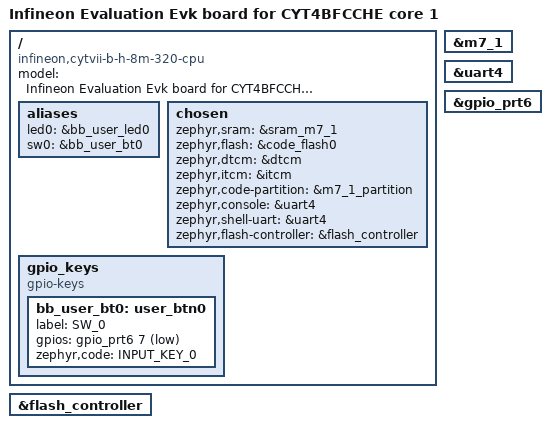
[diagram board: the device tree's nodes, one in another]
/*
 * Copyright (c) 2026 Infineon Technologies AG,
 * or an affiliate of Infineon Technologies AG.
 * Copyright (c) 2026 Linumiz
 *
 * SPDX-License-Identifier: Apache-2.0
 */

/dts-v1/;
#include <arm/infineon/cat1c/traveo/cyt4bf/cyt4bf_m7.dtsi>
#include "cytvii_b_h_8m_320_cpu_common.dtsi"
#include "cytvii_b_h_8m_320_cpu_cyt4bfcche_pinctrl.dtsi"

/ {
	model = "Infineon Evaluation Evk board for CYT4BFCCHE core 1";
	compatible = "infineon,cytvii-b-h-8m-320-cpu", "infineon,cyt4bf";

	aliases {
                led0 = &bb_user_led0;
                sw0 = &bb_user_bt0;
        };

	chosen {
		zephyr,sram = &sram_m7_1;
		zephyr,flash = &code_flash0;
		zephyr,dtcm = &dtcm;
		zephyr,itcm = &itcm;
		zephyr,code-partition = &m7_1_partition;
		zephyr,console = &uart4;
		zephyr,shell-uart = &uart4;
		zephyr,flash-controller = &flash_controller;
	};

	gpio_keys {
                compatible = "gpio-keys";

                bb_user_bt0: user_btn0 {
                        label = "SW_0";
			gpios = <&gpio_prt6 7 (GPIO_PULL_UP | GPIO_ACTIVE_LOW)>;
                        zephyr,code = <INPUT_KEY_0>;
                };
        };
};

&m7_1 {
	status = "okay";
};

&uart4 {
	status = "okay";
};

&gpio_prt6 {
        status = "okay";
};

&flash_controller {
	status = "okay";
};
